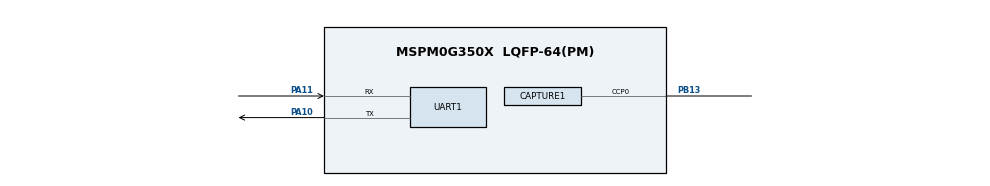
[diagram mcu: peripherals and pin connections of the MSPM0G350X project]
/**
 * @cliArgs --device "MSPM0G350X" --part "Default" --package "LQFP-64(PM)" --product "mspm0_sdk@2.10.00.04"
 * @versions {"tool":"1.26.2+4477"}
 */

/**
 * Import the modules used in this configuration.
 */
const ADC12    = scripting.addModule("/ti/driverlib/ADC12", {}, false);
const ADC121   = ADC12.addInstance();
const CAPTURE  = scripting.addModule("/ti/driverlib/CAPTURE", {}, false);
const CAPTURE1 = CAPTURE.addInstance();
const DAC12    = scripting.addModule("/ti/driverlib/DAC12");
const GPIO     = scripting.addModule("/ti/driverlib/GPIO", {}, false);
const GPIO1    = GPIO.addInstance();
const GPIO2    = GPIO.addInstance();
const GPIO3    = GPIO.addInstance();
const GPIO4    = GPIO.addInstance();
const GPIO5    = GPIO.addInstance();
const GPIO6    = GPIO.addInstance();
const SPI      = scripting.addModule("/ti/driverlib/SPI", {}, false);
const SPI1     = SPI.addInstance();
const SYSCTL   = scripting.addModule("/ti/driverlib/SYSCTL");
const TIMER    = scripting.addModule("/ti/driverlib/TIMER", {}, false);
const TIMER1   = TIMER.addInstance();
const TIMER2   = TIMER.addInstance();
const UART     = scripting.addModule("/ti/driverlib/UART", {}, false);
const UART1    = UART.addInstance();

/**
 * Write custom configuration values to the imported modules.
 */
const divider2       = system.clockTree["HFCLK4MFPCLKDIV"];
divider2.divideValue = 10;

const divider9       = system.clockTree["UDIV"];
divider9.divideValue = 2;

const gate8  = system.clockTree["MFPCLKGATE"];
gate8.enable = true;

const multiplier2         = system.clockTree["PLL_QDIV"];
multiplier2.multiplyValue = 5;

const mux4       = system.clockTree["EXHFMUX"];
mux4.inputSelect = "EXHFMUX_XTAL";

const mux8       = system.clockTree["HSCLKMUX"];
mux8.inputSelect = "HSCLKMUX_SYSPLL0";

const mux10       = system.clockTree["MFPCLKMUX"];
mux10.inputSelect = "MFPCLKMUX_HFCLK";

const pinFunction4     = system.clockTree["HFXT"];
pinFunction4.inputFreq = 40;
pinFunction4.enable    = true;

ADC121.$name                             = "ADC12_0";
ADC121.sampClkSrc                        = "DL_ADC12_CLOCK_ULPCLK";
ADC121.sampClkDiv                        = "DL_ADC12_CLOCK_DIVIDE_8";
ADC121.repeatMode                        = true;
ADC121.trigSrc                           = "DL_ADC12_TRIG_SRC_EVENT";
ADC121.adcMem0chansel                    = "DL_ADC12_INPUT_CHAN_2";
ADC121.configureDMA                      = true;
ADC121.sampCnt                           = 1;
ADC121.enabledDMATriggers                = ["DL_ADC12_DMA_MEM0_RESULT_LOADED"];
ADC121.subChanID                         = 1;
ADC121.powerDownMode                     = "DL_ADC12_POWER_DOWN_MODE_MANUAL";
ADC121.adcPin2Config.$name               = "ti_driverlib_gpio_GPIOPinGeneric0";
ADC121.DMA_CHANNEL.$name                 = "DMA_CH0";
ADC121.DMA_CHANNEL.srcLength             = "HALF_WORD";
ADC121.DMA_CHANNEL.dstLength             = "HALF_WORD";
ADC121.DMA_CHANNEL.configureTransferSize = true;
ADC121.DMA_CHANNEL.transferSize          = 1024;
ADC121.DMA_CHANNEL.enableInterrupt       = true;
ADC121.DMA_CHANNEL.addressMode           = "f2b";

const Board = scripting.addModule("/ti/driverlib/Board", {}, false);

CAPTURE1.$name                      = "CAPTURE_0";
CAPTURE1.captMode                   = "COMBINED";
CAPTURE1.timerPeriod                = "1 s";
CAPTURE1.interrupts                 = ["CC1_DN","ZERO"];
CAPTURE1.peripheral.$assign         = "TIMG12";
CAPTURE1.peripheral.ccp0Pin.$assign = "PB13";
CAPTURE1.ccp0PinConfig.$name        = "ti_driverlib_gpio_GPIOPinGeneric3";

DAC12.dacOutputPinEn     = true;
DAC12.dacAmplifier       = "ON";
DAC12.peripheral.$assign = "DAC0";
DAC12.OutPinConfig.$name = "ti_driverlib_gpio_GPIOPinGeneric7";

GPIO1.$name                         = "GPIO_LEDS";
GPIO1.port                          = "PORTB";
GPIO1.associatedPins[0].assignedPin = "14";
GPIO1.associatedPins[0].$name       = "USER_LED";

GPIO2.$name                         = "ADG704_EN";
GPIO2.port                          = "PORTB";
GPIO2.associatedPins[0].$name       = "PIN_0";
GPIO2.associatedPins[0].assignedPin = "1";

GPIO3.$name                         = "ADG704_A0";
GPIO3.port                          = "PORTB";
GPIO3.associatedPins[0].$name       = "PIN_1";
GPIO3.associatedPins[0].assignedPin = "2";

GPIO4.port                          = "PORTB";
GPIO4.$name                         = "ADG704_A1";
GPIO4.associatedPins[0].$name       = "PIN_2";
GPIO4.associatedPins[0].assignedPin = "3";

GPIO5.port                          = "PORTB";
GPIO5.$name                         = "GPIO_KEY";
GPIO5.associatedPins[0].$name       = "PIN_3";
GPIO5.associatedPins[0].assignedPin = "0";
GPIO5.associatedPins[0].direction   = "INPUT";

GPIO6.$name                          = "LCD_GPIO";
GPIO6.associatedPins.create(4);
GPIO6.associatedPins[0].$name        = "CS";
GPIO6.associatedPins[1].$name        = "DC";
GPIO6.associatedPins[2].$name        = "RST";
GPIO6.associatedPins[2].assignedPort = "PORTB";
GPIO6.associatedPins[2].assignedPin  = "15";
GPIO6.associatedPins[3].$name        = "BL";
GPIO6.associatedPins[3].assignedPort = "PORTB";
GPIO6.associatedPins[3].assignedPin  = "16";

SPI1.$name                              = "LCD_SPI";
SPI1.frameFormat                        = "MOTO3";
SPI1.polarity                           = "1";
SPI1.sclkPinConfig.$name                = "ti_driverlib_gpio_GPIOPinGeneric4";
SPI1.sclkPinConfig.direction            = scripting.forceWrite("OUTPUT");
SPI1.sclkPinConfig.onlyInternalResistor = scripting.forceWrite(false);
SPI1.sclkPinConfig.passedPeripheralType = scripting.forceWrite("Digital");
SPI1.mosiPinConfig.$name                = "ti_driverlib_gpio_GPIOPinGeneric5";
SPI1.mosiPinConfig.direction            = scripting.forceWrite("OUTPUT");
SPI1.mosiPinConfig.hideOutputInversion  = scripting.forceWrite(false);
SPI1.mosiPinConfig.onlyInternalResistor = scripting.forceWrite(false);
SPI1.mosiPinConfig.passedPeripheralType = scripting.forceWrite("Digital");
SPI1.misoPinConfig.$name                = "ti_driverlib_gpio_GPIOPinGeneric6";
SPI1.misoPinConfig.onlyInternalResistor = scripting.forceWrite(false);
SPI1.misoPinConfig.passedPeripheralType = scripting.forceWrite("Digital");
SPI1.peripheral.$assign                 = "SPI1";

SYSCTL.forceDefaultClkConfig = true;
SYSCTL.clockTreeEn           = true;
SYSCTL.MFPCLKEn              = true;
SYSCTL.MFPCLKSource          = "HFCLK";

TIMER1.$name                       = "TIMER_0";
TIMER1.timerClkPrescale            = 9;
TIMER1.timerMode                   = "PERIODIC";
TIMER1.timerPeriod                 = "10us";
TIMER1.event1ControllerInterruptEn = ["ZERO_EVENT"];
TIMER1.event1PublisherChannel      = 1;
TIMER1.peripheral.$assign          = "TIMG7";

TIMER2.$name              = "TIMER_GATE";
TIMER2.timerClkPrescale   = 256;
TIMER2.timerMode          = "PERIODIC";
TIMER2.timerPeriod        = "100 ms";
TIMER2.interrupts         = ["LOAD"];
TIMER2.peripheral.$assign = "TIMA1";

UART1.$name                    = "UART_0";
UART1.targetBaudRate           = 115200;
UART1.enableFIFO               = true;
UART1.peripheral.rxPin.$assign = "PA11";
UART1.peripheral.txPin.$assign = "PA10";
UART1.txPinConfig.$name        = "ti_driverlib_gpio_GPIOPinGeneric1";
UART1.rxPinConfig.$name        = "ti_driverlib_gpio_GPIOPinGeneric2";

/**
 * Pinmux solution for unlocked pins/peripherals. This ensures that minor changes to the automatic solver in a future
 * version of the tool will not impact the pinmux you originally saw.  These lines can be completely deleted in order to
 * re-solve from scratch.
 */
pinFunction4.peripheral.$suggestSolution           = "SYSCTL";
pinFunction4.peripheral.hfxInPin.$suggestSolution  = "PA5";
pinFunction4.peripheral.hfxOutPin.$suggestSolution = "PA6";
ADC121.peripheral.$suggestSolution                 = "ADC0";
ADC121.peripheral.adcPin2.$suggestSolution         = "PA25";
ADC121.DMA_CHANNEL.peripheral.$suggestSolution     = "DMA_CH0";
Board.peripheral.$suggestSolution                  = "DEBUGSS";
Board.peripheral.swclkPin.$suggestSolution         = "PA20";
Board.peripheral.swdioPin.$suggestSolution         = "PA19";
DAC12.peripheral.OutPin.$suggestSolution           = "PA15";
GPIO1.associatedPins[0].pin.$suggestSolution       = "PB14";
GPIO2.associatedPins[0].pin.$suggestSolution       = "PB1";
GPIO3.associatedPins[0].pin.$suggestSolution       = "PB2";
GPIO4.associatedPins[0].pin.$suggestSolution       = "PB3";
GPIO5.associatedPins[0].pin.$suggestSolution       = "PB0";
GPIO6.associatedPins[0].pin.$suggestSolution       = "PA12";
GPIO6.associatedPins[1].pin.$suggestSolution       = "PA13";
GPIO6.associatedPins[2].pin.$suggestSolution       = "PB15";
GPIO6.associatedPins[3].pin.$suggestSolution       = "PB16";
SPI1.peripheral.sclkPin.$suggestSolution           = "PA17";
SPI1.peripheral.mosiPin.$suggestSolution           = "PA18";
SPI1.peripheral.misoPin.$suggestSolution           = "PA16";
UART1.peripheral.$suggestSolution                  = "UART0";
